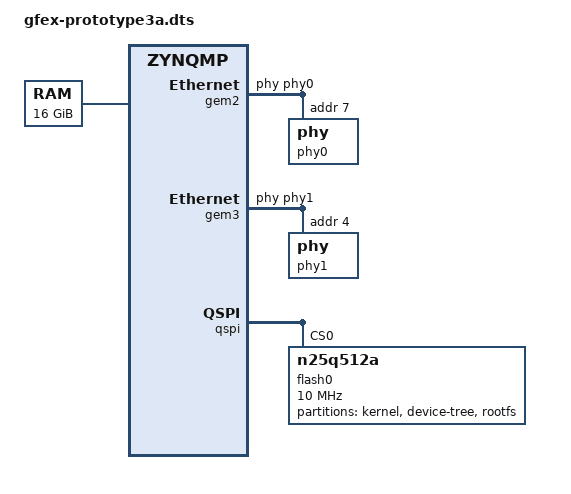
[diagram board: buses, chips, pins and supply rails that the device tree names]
/*
 * CAUTION: This file is automatically generated by Xilinx.
 * Version:  
 * Today is: Tue Dec  5 16:03:00 2017
 */


/dts-v1/;
/include/ "zynqmp.dtsi"
/include/ "zynqmp-clk-ccf.dtsi"
/include/ "pl.dtsi"
/include/ "pcw.dtsi"
/ {
	chosen {
		bootargs = "earlycon clk_ignore_unused";
		stdout-path = "serial0:115200n8";
	};
	aliases {
		ethernet0 = &gem2;
		ethernet1 = &gem3;
		serial0 = &uart0;
		spi1 = &axi_quad_spi_0;
		spi0 = &qspi;
		spi2 = &spi0;
		spi3 = &spi1;
	};
	memory {
		device_type = "memory";
		reg = <0x0 0x0 0x0 0x80000000>, <0x00000008 0x00000000 0x00000003 0x80000000>;
	};
};

/** Note: gem2/gem3 switched between v3a and v3b **/
&gem2 {
    local-mac-address = [00 0a 35 00 00 00];
    phy-handle = <&phy0>;
    phy0: phy@7 {
        reg = <0x7>;
        ti,rx-internal-delay = <0x8>;
        ti,tx-internal-delay = <0xa>;
        ti,fifo-depth = <0x1>;
    };
};

&gem3 {
    local-mac-address = [00 0a 35 00 00 01];
    phy-handle = <&phy1>;
    phy1: phy@4 {
        reg = <0x4>;
        ti,rx-internal-delay = <0x8>;
        ti,tx-internal-delay = <0xa>;
        ti,fifo-depth = <0x1>;
    };
};

&qspi {
    flash0: flash@0 {
        compatible = "n25q512a", "micron,m25p80";
        reg = <0x0>;
        #address-cells = <1>;
        #size-cells = <1>;
        spi-max-frequency = <10000000>;
        spi-rx-bus-width = <0x4>;
        spi-tx-bus-width = <0x1>;
        is-dual = <0x1>;
        partition@qspi-linux {
                  label = "kernel";
                  reg = <0x02000000 0x01000000>;
        };
        partition@qspi-device-tree {
                  label = "device-tree";
                  reg = <0x03000000 0x01000000>;
        };
        partition@qspi-rootfs {
                  label = "rootfs";
                  reg = <0x04000000 0x04000000>;
        };
    };
};
